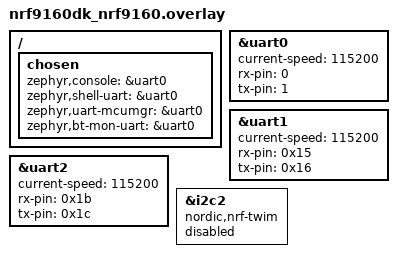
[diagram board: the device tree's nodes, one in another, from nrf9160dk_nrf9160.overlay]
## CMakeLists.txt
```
# SPDX-License-Identifier: Apache-2.0

cmake_minimum_required(VERSION 3.13.1)

set(DTC_OVERLAY_FILE "${CMAKE_CURRENT_SOURCE_DIR}/${BOARD}.overlay")

find_package(Zephyr REQUIRED HINTS $ENV{ZEPHYR_BASE})
project(hello_world)

target_include_directories(app PRIVATE
src)

target_sources(app PRIVATE
src/main.cpp
src/memtracer.cpp
src/eventpack.cpp
src/eventmanager.cpp
src/watchdog.cpp
src/heartbeat.cpp
src/test_uart00.cpp
src/test_uart01.cpp
src/test_uart02.cpp)
```

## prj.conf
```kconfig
########################################
#################Atrack#################
########################################
#recommand use non-secure mode because lte lib must in non-secure
# -Og debug can change to -O0, refer to compiler_flags.cmake
CONFIG_DEBUG=y

# enable cpp
CONFIG_CPLUSPLUS=y
CONFIG_STD_CPP11=y
CONFIG_LIB_CPLUSPLUS=y

# enable libs
CONFIG_NEWLIB_LIBC=y
CONFIG_NEWLIB_LIBC_FLOAT_PRINTF=y
CONFIG_FPU=y

# 3 uarts move to external pin, plz use usb-jlink JLinkRTTViewerExe watch log
CONFIG_UART_CONSOLE=n
CONFIG_USE_SEGGER_RTT=y
CONFIG_RTT_CONSOLE=y
#for input message
CONFIG_SEGGER_RTT_BUFFER_SIZE_DOWN=2048
CONFIG_SEGGER_RTT_BUFFER_SIZE_UP=2048

# reboot utility
CONFIG_REBOOT=y

# Fatal error reboot
CONFIG_WATCHDOG=y

# Json utility, if u need
###CONFIG_JSON_LIBRARY=y

# enable mcuboot prevent .text overflow, need pip3 install cryptography
CONFIG_BOOTLOADER_MCUBOOT=y
```

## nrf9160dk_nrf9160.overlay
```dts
/*
 * Copyright (c) 2021 Nordic Semiconductor ASA
 *
 * SPDX-License-Identifier: Apache-2.0
 */

/ {
	chosen {
		zephyr,console     = &uart0;
		zephyr,shell-uart  = &uart0;
		zephyr,uart-mcumgr = &uart0;
		zephyr,bt-mon-uart = &uart0;
	};
};

&uart0 {
        current-speed = <115200>;
        status = "okay";
        rx-pin = <0>;
        tx-pin = <1>;
        /delete-property/ cts-pin;
        /delete-property/ rts-pin;
};

&uart1 {
        current-speed = <115200>;
        status = "okay";
        rx-pin = <0x15>;
        tx-pin = <0x16>;
        /delete-property/ cts-pin;
        /delete-property/ rts-pin;
};

&uart2 {
        current-speed = <115200>;
        status = "okay";
        rx-pin = <0x1b>;
        tx-pin = <0x1c>;
        /delete-property/ cts-pin;
        /delete-property/ rts-pin;
};

/*prevent irq conflict with uart2*/
&i2c2 {
        compatible = "nordic,nrf-twim";
		status = "disabled";
};
```

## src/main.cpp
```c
/*
 * Copyright (c) 2012-2014 Wind River Systems, Inc.
 *
 * SPDX-License-Identifier: Apache-2.0
 */

#if defined(__ZEPHYR__)
#include <zephyr.h>
#include <device.h>
#include <devicetree.h>
#include <drivers/uart.h>
#include <drivers/i2c.h>
#include <drivers/sensor.h>
#include <drivers/flash.h>
#include <storage/flash_map.h>
//#include <data/json.h>
#endif

#include <stdint.h>
#include <unistd.h>
#include <stdio.h>
#include <stddef.h>
#include <string.h> //for memset
#include <math.h>

#include <string>
#include <list>
#include <vector>
#include <map>

#if !defined(__ZEPHYR__) //for x86
#include "memtracer.h"
#endif

#include "global.h"
#include "eventfunctor.h"
#include "eventpack.h"
#include "eventmanager.h"
#include "watchdog.h"
#include "heartbeat.h"
#include "test_uart00.h"
#include "test_uart01.h"
#include "test_uart02.h"

#define THREAD_STACKSIZE  4096

#if defined(__ZEPHYR__)
K_THREAD_STACK_DEFINE(stack_application_area, THREAD_STACKSIZE);
static struct k_work_q    s_application_work_q;
#endif

//~/ncs/zephyr/include/data/json.h
/*static void test_json_obj_arr_encoding()
{
  typedef struct _test_struct_t
  {
    //char  some_string[64]; //will crash in json lib
    char* some_string;
    int   some_int;
    bool  some_bool;
  }test_struct_t;

  test_struct_t ts = 
  {
    //.some_string  = {0},
    .some_string  = "zephyr 123",
    .some_int     = 42,
    .some_bool    = true,
  };

  struct json_obj_descr test_descr[] = 
  {
    JSON_OBJ_DESCR_PRIM(test_struct_t, some_string,  JSON_TOK_STRING),
    JSON_OBJ_DESCR_PRIM(test_struct_t, some_int,     JSON_TOK_NUMBER),
    JSON_OBJ_DESCR_PRIM(test_struct_t, some_bool,    JSON_TOK_TRUE),
  };

  char buffer[256] = {0};
  
  json_obj_encode_buf(test_descr, ARRAY_SIZE(test_descr), &ts, buffer, sizeof(buffer));
  
  printk("%s\n", buffer);
}

static void test_json_obj_arr_decoding()
{
  struct  test_struct 
  {
    char*   some_string;
    int     some_int;
    bool    some_bool;
  };

  struct test_struct ts = 
  {
    .some_string  = "zephyr 000",
    .some_int     = 0,
    .some_bool    = false,
  };

  struct json_obj_descr test_descr[] = 
  {
    JSON_OBJ_DESCR_PRIM(struct test_struct, some_string,  JSON_TOK_STRING),
    JSON_OBJ_DESCR_PRIM(struct test_struct, some_int,     JSON_TOK_NUMBER),
    JSON_OBJ_DESCR_PRIM(struct test_struct, some_bool,    JSON_TOK_TRUE),
  };

  char encoded[] =  "{\"some_string\":\"zephyr 123\","
                    "\"some_int\":42,\"some_bool\":true,"
                    "}";

  json_obj_parse(encoded, sizeof(encoded) - 1, test_descr, ARRAY_SIZE(test_descr), &ts);

  printk("%s : %d : %d\n", ts.some_string, ts.some_int, ts.some_bool);
}*/


//"memory" = memory barrier, save to register not memory, in -Og -O1 -O2 -O3 of gcc
int test_asm00()
{
  int ret;
  uint32_t arm_reg_input[4] = {0x01};

  arm_reg_input[0] += 1;
  __asm__ volatile("" ::: "memory");
  arm_reg_input[1] += 1;
 
  ret = arm_reg_input[0]+arm_reg_input[1];
  
  return ret;
}

int test_asm01()
{
  int ret;
  uint32_t arm_reg_input[4] = {0x01};
  
  __asm__ volatile("" ::: "memory");

  arm_reg_input[0] += 1;
  arm_reg_input[1] += 1;

  ret = arm_reg_input[0]+arm_reg_input[1];

  return ret;
}

//check https://docs.zephyrproject.org/latest/reference/kernel/threads/index.html?highlight=k_thread_create#c.k_thread_create
#if defined(__ZEPHYR__)
void main(void)
#else
int main(int argc, char* argv[])
#endif
{
  printf("main start\n");

#if defined(__ZEPHYR__)
  k_work_q_start( &s_application_work_q, 
                  stack_application_area,  
                  K_THREAD_STACK_SIZEOF(stack_application_area),
                  CONFIG_SYSTEM_WORKQUEUE_PRIORITY);
  
  watchdog_init_and_start(&s_application_work_q);//Hank request work

  uint32_t output           = 0x01;
  uint32_t arm_reg_input[4] = {0};
  arm_reg_input[0]          = 0x02;
  arm_reg_input[1]          = 0x03;
  arm_reg_input[2]          = 0x04;
  arm_reg_input[3]          = 0x05;
  
  __asm__ volatile 
  ( 
    "add r0, r1 \n\t"
    "add r0, r2 \n\t"
    "add r0, r3 \n\t"
    "mov %0, r0 \n\t"
    : "=r"(output)
    : "r"(arm_reg_input[0]), "r"(arm_reg_input[1]), "r"(arm_reg_input[2]), "r"(arm_reg_input[3])
  );
#endif

  test_asm00();
  test_asm01();

  HeartBeat_Init();
  Test_Uart00_Init();
  Test_Uart01_Init();
  Test_Uart02_Init();

  for(int i=0; i<30; i++)
  {
    printf("main loop: %d\n", i);
    HeartBeat_BroadCast();

#if defined(__ZEPHYR__)
    k_usleep(SLEEP_HEARTBEAT);
#else
    usleep(SLEEP_HEARTBEAT);
#endif

    HeartBeat_LiveCheck();

#if defined(__ZEPHYR__)
    k_usleep(SLEEP_HEARTBEAT);
#else
    usleep(SLEEP_HEARTBEAT);
#endif
  }

  Test_Uart00_Destory(); //for test seq
  Test_Uart01_Destory();
  Test_Uart02_Destory();
  HeartBeat_Destory();


  EventManager::Free();

  //////////////////enable this can see memory leak, in debug mode/////////////////////
  //int* a = new int[1];
  //int* a = (int*)malloc(sizeof(int));
#if !defined(__ZEPHYR__) //for x86
  dumpAlloc();
#endif

  printf("main end\n");
}
```

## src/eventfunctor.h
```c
#ifndef EVENT_FUNCTOR_H
#define EVENT_FUNCTOR_H

template<class ParamInfo> 
class EventFunctorBase
{
public:
	virtual ~EventFunctorBase()	{ }
	virtual void*	GetMember()				= 0;
	virtual void	Call(ParamInfo* event)	= 0;
};

template<class ParamInfo> 
class EventFunctor : public EventFunctorBase<ParamInfo>
{
public:
	typedef void (*MemberPtr)(ParamInfo*); //ParamInfo is func's paramater

	EventFunctor(MemberPtr callmember)
	{
		m_pCallMember = callmember;
	}

	virtual ~EventFunctor()	{ }

	virtual void* GetMember() 
	{ 
		return (void*)m_pCallMember;
	}

	virtual void Call(ParamInfo* event)
	{ 
		(*m_pCallMember)(event);
	}

private:
	MemberPtr	m_pCallMember;
};

#endif // I_FUNCTOR_H
```

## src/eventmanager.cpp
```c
#if defined(__ZEPHYR__)
#include <zephyr.h>
#else
#include <pthread.h>
#endif

#include <stddef.h>
#include <vector>
#include <map>

#if !defined(__ZEPHYR__) //for x86
#include "memtracer.h"
#endif

#include "eventfunctor.h"
#include "eventpack.h"
#include "eventmanager.h"

#if defined(__ZEPHYR__)
K_MUTEX_DEFINE(s_evtmanager_mutex);
#else
pthread_mutex_t s_evtmanager_mutex;
#endif

enum {
EVENTMGR_CONNECT,
EVENTMGR_DISCONNECT,
EVENTMGR_SEND
};

static EventManager* evtmanager_instance = NULL;

EventManager* EventManager::Get()
{
    if (!evtmanager_instance)
      evtmanager_instance = new EventManager();

    return evtmanager_instance;
}

void EventManager::Free()
{
    if( evtmanager_instance )
    {
      delete evtmanager_instance;
      evtmanager_instance = NULL;
    }
}

EventManager::EventManager()
{
#if !defined(__ZEPHYR__)
  pthread_mutex_init(&s_evtmanager_mutex, NULL);
#endif
}

EventManager::~EventManager()
{
#if !defined(__ZEPHYR__)
  pthread_mutex_destroy(&s_evtmanager_mutex);
#endif
}

void EventManager::ProcessEvent(int type, int messageID, void* callmember, EventPack* event)
{
#if defined(__ZEPHYR__)
    k_mutex_lock(&s_evtmanager_mutex, K_FOREVER);
#else
    pthread_mutex_lock(&s_evtmanager_mutex);
#endif

    unsigned int                      i;
    unsigned int                      size;
    unsigned int                      shift_p;
    unsigned int                      remain_size_vit;
    unsigned int                      remain_size_mit;
    EventMessageSlot_Vector::iterator vit;
    EventMessageSlot_Map::iterator    mit;
    EventMessageSlot_Map::iterator    tmp;
    EventFunctor<EventPack>*          functor;

    switch(type)
    {
        case EVENTMGR_CONNECT:
                functor = new EventFunctor<EventPack>((EventFunctor<EventPack>::MemberPtr)callmember);
                m_EventMessageSlotMap[messageID].push_back(functor);
                break;

        case EVENTMGR_DISCONNECT:
                mit             = m_EventMessageSlotMap.begin();
                remain_size_mit = m_EventMessageSlotMap.size();
                while(remain_size_mit > 0)
                {
                    shift_p         = 0;
                    remain_size_vit = mit->second.size();

                    while(remain_size_vit > 0)
                    {
                        if( mit->second[shift_p]->GetMember() == callmember )
                        {
                          vit = mit->second.begin() + shift_p;
                          delete *vit; //delete vector
                          mit->second.erase(vit);
                        }
                        else
                        {
                          shift_p++;
                        }

                        remain_size_vit--;
                    }

                    //empty slot remove
                    if( mit->second.size() <= 0 )
                    {
                        tmp = mit; //content copy
                        //mit++;
                        //m_EventMessageSlotMap.erase(tmp);
                        mit = m_EventMessageSlotMap.erase(tmp);
                    }
                    else
                    {
                        mit++;
                    }

                    remain_size_mit--;
                }
                break;

        case EVENTMGR_SEND:
#if !defined(__ZEPHYR__) || defined(CONFIG_DEBUG)
                printf("Start Source=%d~~~\n", event->GetSourceId());
#endif
                mit = m_EventMessageSlotMap.find(event->GetMessageId());
                if( mit != m_EventMessageSlotMap.end() ) //prevent null map
                {
                    size  = mit->second.size();

                    for ( i=0; i<size; i++)
                            mit->second[i]->Call(event);
                }
#if !defined(__ZEPHYR__) || defined(CONFIG_DEBUG)
                printf("End   Source=%d###\n", event->GetSourceId());
#endif
                break;
    }


#if defined(__ZEPHYR__)
    k_mutex_unlock(&s_evtmanager_mutex);
#else
    pthread_mutex_unlock(&s_evtmanager_mutex);
#endif
}

void EventManager::ConnectEventSlot(int messageID, void* callmember)
{
    this->ProcessEvent(EVENTMGR_CONNECT, messageID, callmember, NULL);
}

void EventManager::DisconnectEventSlot(void* callmember)
{
    this->ProcessEvent(EVENTMGR_DISCONNECT, 0, callmember, NULL);
}

void EventManager::SendEventMessage(EventPack* event)
{
    this->ProcessEvent(EVENTMGR_SEND, 0, NULL, event);
}
```

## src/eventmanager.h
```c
#ifndef EVENT_MANAGER_H
#define EVENT_MANAGER_H

class EventManager
{
public:
	
	typedef std::vector<EventFunctorBase<EventPack>*>	EventMessageSlot_Vector;
	typedef std::map<int, EventMessageSlot_Vector>		EventMessageSlot_Map; //<message_ID, EventPack_Vector>

    static EventManager* Get();
    static void Free();
	EventManager();
	~EventManager();

	// event sinks
	//void	ConnectEventSlot(int messageID, EventFunctorBase<EventPack>* functor);
	void 	ProcessEvent(int type, int messageID, void* callmember, EventPack* event);
	void	ConnectEventSlot(int messageID, void* callmember);
	void	DisconnectEventSlot(void* callmember);
	void	SendEventMessage(EventPack* event);
	
private:
	// event sinks
	EventMessageSlot_Map	m_EventMessageSlotMap;
};

#endif /// EVENT_MANAGER_H
```

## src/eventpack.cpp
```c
#include <stdio.h>

#if !defined(__ZEPHYR__) //for x86
#include "memtracer.h"
#endif

#include "eventfunctor.h"
#include "eventpack.h"

int EVT_HEARTBEAT_BROADCAST = 0x0000;
int EVT_HEARTBEAT_FEEDBACK  = 0x0001;
int SRC_HEARTBEAT           = 0x0002;
int SRC_TEST_UART00         = 0x0003;
int SRC_TEST_UART01         = 0x0004;
int SRC_TEST_UART02         = 0x0005;

EventPack::EventPack( int messageid )
{
  this->SetMessageId(messageid);
}

EventPack::~EventPack()
{
}

void EventPack::SetMessageId( int id ) 
{ 
  m_messageid = id; 
}

int EventPack::GetMessageId() 
{ 
  return m_messageid; 
}

void EventPack::SetSourceId( int id ) 
{ 
  m_sourceid = id;
}
	
int EventPack::GetSourceId() 
{ 
  return m_sourceid; 
}

void EventPack::SetText( char* text ) 
{ 
  sprintf(m_text, "%s", text);
}
	
char* EventPack::GetText() 
{ 
  return m_text; 
}
```

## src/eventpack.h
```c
#ifndef SDK_EVENT_H
#define SDK_EVENT_H

extern int EVT_HEARTBEAT_BROADCAST;
extern int EVT_HEARTBEAT_FEEDBACK;
extern int SRC_HEARTBEAT;
extern int SRC_TEST_UART00;
extern int SRC_TEST_UART01;
extern int SRC_TEST_UART02;

class EventPack
{
public:
  EventPack( int messageid );
  ~EventPack();
      
  void  SetMessageId( int id );
  int	GetMessageId();

  void	SetSourceId( int id );
  int	GetSourceId();

  void	SetText( char* text );
  char*	GetText();

/******************************/      
  int		m_messageid;
  int		m_sourceid;
  char		m_text[256];
};

#endif	/// #define CONNECT_EVENT_H
```

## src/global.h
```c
#ifndef ATRACK_GLOBAL_H
#define ATRACK_GLOBAL_H

#define SLEEP_MINIMUM     100000  //for short time recv
#define SLEEP_LOOP        500000  //for thread sleep
#define SLEEP_HEARTBEAT   6000000 //6 sec

#endif
```

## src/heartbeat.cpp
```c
#if defined(__ZEPHYR__)
#include <zephyr.h>
#include <drivers/uart.h>
#include <power/reboot.h>
#endif

#include <stdint.h>
#include <string.h>
#include <stdio.h>
#include <vector>
#include <map>

#if !defined(__ZEPHYR__) //for x86
#include "memtracer.h"
#endif

#include "global.h"

#include "eventfunctor.h"
#include "eventpack.h"
#include "eventmanager.h"
#include "heartbeat.h"

std::map<int, bool> s_heartbeat_live_map;

void HeartBeat_BroadCast()
{
  printf("BroadCast\n");
  
  EventPack* event = new EventPack(EVT_HEARTBEAT_BROADCAST);

  event->SetSourceId(SRC_HEARTBEAT);
  EventManager::Get()->SendEventMessage(event);

  delete event;
}

static void HeartBeat_FeedBack(EventPack* event)
{
  int srcid = event->GetSourceId();
  s_heartbeat_live_map[srcid] = true;
}

int HeartBeat_LiveCheck()
{
  uint32_t  total_live;
  char      buf[64];
  
  total_live = 0;
  for (auto& mit : s_heartbeat_live_map)
  {
    sprintf(buf,"id=%d, live=%d\n", mit.first, mit.second);
    printf("%s", buf);
    
    if( mit.second )
      total_live++;

    mit.second = false;
  }

  if( total_live < s_heartbeat_live_map.size() )
  {
#if defined(__ZEPHYR__)
    sys_reboot(0);
#else
    exit(0);
#endif
  }
  
    
  return total_live;
}

void HeartBeat_Init()
{
  s_heartbeat_live_map.insert({SRC_TEST_UART00, false });
  s_heartbeat_live_map.insert({SRC_TEST_UART01, false });
  s_heartbeat_live_map.insert({SRC_TEST_UART02, false });

  //EventManager::Get()->ConnectEventSlot(EVT_HEARTBEAT_FEEDBACK, new EventFunctor<EventPack>(&HeartBeat_FeedBack));
  EventManager::Get()->ConnectEventSlot(EVT_HEARTBEAT_FEEDBACK, (void*)&HeartBeat_FeedBack);
}

void HeartBeat_Destory()
{
  EventManager::Get()->DisconnectEventSlot((void*)&HeartBeat_FeedBack);

  s_heartbeat_live_map.clear();
}
```

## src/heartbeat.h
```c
#ifndef HEARTBEAT_H
#define HEARTBEAT_H

extern void HeartBeat_BroadCast();
extern int  HeartBeat_LiveCheck();
extern void HeartBeat_Init();
extern void HeartBeat_Destory();

#endif
```

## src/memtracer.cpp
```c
#if !defined(__ZEPHYR__) //for x86

#include <assert.h>
#include <stdio.h>
#include <stdlib.h>
#include <string.h>

#define MEM_TRACER_C 1
#include "memtracer.h"

#ifdef __cplusplus
extern "C" {
#endif
// Allocation descriptors HashMap related functions
static size_t genHash(size_t max, void* ptr)
{
	size_t key= (size_t)ptr;
	return (key % max);
}

static int nextNotPow2(int num)
{
	int nextnotpow2=num;
	while ( (nextnotpow2!=0) && ((nextnotpow2 & (nextnotpow2-1)) == 0) ) 
	{
		nextnotpow2++;
	}
	return nextnotpow2;
}

/**
   Returns an empty hash of the chosen size
 */
allochashmap* hashmap_Init(int size)
{
	int asize=nextNotPow2(size);
	allochashmap* map=(allochashmap*) malloc(sizeof(allochashmap));
	assert((NULL!=map) &&  MSG_ERR_HM_MALLOC);
	map->size=asize;
	map->table=(allocnode**)calloc(asize,sizeof(allocnode));
	if (NULL==map->table) 
	{
		free(map);
		map=NULL;
	}
	assert((NULL!=map) &&  MSG_ERR_HM_MALLOC);
	return(map);
}

/**
   Free the hash with ALL its content, leaked pointers will be freed.
 */
void hashmap_Destroy(allochashmap* map)
{
	size_t i=0;
	for(i=0; i<map->size; ++i) 
	{
		while(map->table[i] != NULL)
		{
			allocnode* next=map->table[i]->next;
			free(map->table[i]->info->file);
			//free(map->table[i]->info->ptr); //external pointer as _CrtDumpMemoryLeaks();
			free(map->table[i]->info);
			free(map->table[i]);
			map->table[i]=next;
		}
	}
	free(map->table);
	map->table=NULL;
	free(map);
	map=NULL;
}

/**
   Remove the allocation descriptor of the given pointer, returns true: found, false:no found
 */
bool hashmap_Delete(allochashmap* map, void* ptr)
{
	size_t		idx	= genHash(map->size, ptr);
	allocnode*	cur	= map->table[idx];
	allocnode*	prev= map->table[idx];

	while(cur != NULL)
	{
		if (cur->info->ptr == ptr) 
		{
			//allocnode* found=cur;
			if (prev==cur) 
			{
				map->table[idx]=cur->next;
			}
			else
			{
				prev->next=cur->next;
			}
			
			free(cur->info->file);	//free(found->info->file);
			free(cur->info);		//free(found->info);
			free(cur);				//free(found);
			
			return true;
		}
		else
		{
			prev=cur;
			cur=cur->next;
		}
	}
	
	return false;
}

/**
   Print out the content of the hashmap using the given function as allocated block address - block size and stats on the load
 */
void hashmap_Print(allochashmap* map, int outp(const char *format, ...))
{
	//int	load	= 0;
	int		isfirst	= 1;
	
	for(size_t i=0; i<map->size; ++i)
	{
		allocnode* nextn = map->table[i];
		
		//if (nextn != NULL)
		//	load++;
		while(nextn != NULL)
		{
			if (isfirst)
			{
				isfirst = 0;
				outp("--- Memory Leak status ---\n");
			}
			
			outp("Addr:0x%016llX - Size: %llu allocated in %s:%d\n", (unsigned long long)nextn->info->ptr, (unsigned long long)nextn->info->size, nextn->info->file, nextn->info->line);
			nextn = nextn->next;
		}
	}
}

/**
   Insert a new allocation descriptor, returns hash key (pointer descriptor idx)
 */
size_t hashmap_Insert(allochashmap* map, allocdescr* data)
{
	size_t idx=genHash(map->size, data->ptr);
	allocnode* newnode= (allocnode*) calloc(1,sizeof(allocnode));
	assert((NULL!=newnode) &&  MSG_ERR_HM_MALLOC);
	newnode->info=data;
	newnode->next=map->table[idx];
	map->table[idx]=newnode;
	return idx;
}

/**
   Build an allocation descriptor
 */
allocdescr* buildAllocdescr(void* ptr, size_t size, const char* filename, int line)
{
	allocdescr* newn=(allocdescr*)malloc(sizeof(allocdescr));
	newn->ptr=ptr;
	newn->size=size;
	newn->file=(char*) malloc(50);
	strcpy(newn->file,filename);
	newn->line=line;
	return newn;
}

//--------------------------------------------------------------------------------------------
static allochashmap* allocMap=NULL;

void tracingInit()
{
	if (NULL == allocMap) 
	{
		allocMap=hashmap_Init(ALLOC_TABLE_SIZE);
	}
}

void* tracingMalloc(size_t size, const char* name, int line)
{
	tracingInit();
	void* ptr=malloc(size);
	hashmap_Insert(allocMap,buildAllocdescr(ptr,size,name,line));
	return ptr;
}

void* tracingRealloc(void* ptr, int size, const char* name, int line)
{
	tracingInit();
	hashmap_Delete(allocMap,ptr);
	void* ptrnew=realloc(ptr,size);
	hashmap_Insert(allocMap,buildAllocdescr(ptrnew,size,name,line));
	return ptr;
}

void* tracingCalloc(int num, int size, const char* name, int line)
{
	tracingInit();
	void* ptr=calloc(num,size);
	hashmap_Insert(allocMap,buildAllocdescr(ptr,num*size,name,line));
	return ptr;
}

void tracingFree(void* ptr)
{
	tracingInit();
	hashmap_Delete(allocMap,ptr);
	free(ptr);
}

void dumpAlloc()
{
    tracingInit();
	hashmap_Print(allocMap,&printf);
	hashmap_Destroy(allocMap);
}
#ifdef __cplusplus
}
#endif

#ifdef __cplusplus
void* operator new(size_t size) throw()
{
	return tracingMalloc(size,"-N/A-",0);
}

void* operator new(size_t size, const char* name, int line)
{
	return tracingMalloc(size,name,line);
}

//void* operator new[] (size_t size) throw(std::bad_alloc)
void* operator new[](size_t size) throw()
{
	return tracingMalloc(size,"-N/A-",0);
}

void * operator new[] (size_t size, const char* name, int line)
{
	return tracingMalloc(size,name,line);
}

void operator delete(void* ptr) throw()
{
	tracingFree(ptr);
}

void operator delete(void* ptr, const char* name, int line)
{
	tracingFree(ptr);
}

void operator delete[](void* ptr) throw()
{
	tracingFree(ptr);
}

void operator delete[](void* ptr, const char* name, int line)
{
	tracingFree(ptr);
}
#endif //end __cplusplus

#endif //end !defined(__ZEPHYR__)
```

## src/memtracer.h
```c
#ifndef MEM_TRACER_H
#define MEM_TRACER_H

#include <stddef.h>

#ifdef __cplusplus
#include <new>
extern "C" {
#endif

#define MSG_ERR_HM_MALLOC "malloc() failed for allocation descriptors hashmap."

// Allocation descriptors hashmap size, increase to lower the load shown by dumpAlloc
//#define ALLOC_TABLE_SIZE 1733
#define ALLOC_TABLE_SIZE 4096

// Allocation descriptor hashmap structs
typedef struct allocdescr
{
	void*	ptr;
	char*	file;
	int		line;
	size_t	size;
} allocdescr;

typedef struct allocnode
{
	allocdescr*			info;
	struct allocnode*	next;
} allocnode;

typedef struct allochashmap
{
	size_t		size;
	allocnode** table;
} allochashmap;

void*	tracingMalloc(size_t size, const char* name, int line);
void*	tracingRealloc(void* ptr, int size, const char* name, int line);
void*	tracingCalloc(int num, int size, const char* name, int line);
void	tracingFree(void* ptr);
void	dumpAlloc();

#ifndef MEM_TRACER_C
	#define malloc(s) tracingMalloc(s,__FILE__,__LINE__)
	#define realloc(p,s) tracingRealloc(p,s,__FILE__,__LINE__)
	#define calloc(n,s) tracingCalloc(n,s,__FILE__,__LINE__)
	#define free(p) tracingFree(p)
#endif //ifndef MEM_TRACER_C

#ifdef __cplusplus
}
#endif


#ifndef MEM_TRACER_C
#ifdef __cplusplus
	//void*	operator new(size_t) throw(std::bad_alloc);
	void*	operator new(size_t) throw();
	void*	operator new(size_t, const char* name, int line);
	//void*	operator new[] (size_t) throw(std::bad_alloc);
	void*	operator new[](size_t) throw();
	void*	operator new[] (size_t, const char* name, int line);
	
	void	operator delete(void*) throw();
	void	operator delete(void*, const char* name, int line);
	void	operator delete[](void*) throw();
	void	operator delete[](void*, const char* name, int line);
			
	#define tracingNew new (__FILE__,__LINE__)
	#define tracingDelete delete
	#define new tracingNew
	#define delete tracingDelete
#endif //ifdef _cplusplus
#endif //ifndef MEM_TRACER_C


#endif //ifndef MEM_TRACER_H 
```

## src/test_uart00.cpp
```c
#if defined(__ZEPHYR__)
#include <zephyr.h>
#include <drivers/uart.h>
#else
#include <pthread.h>
#endif
#include <unistd.h>
#include <string.h>
#include <stdio.h>
#include <vector>
#include <map>

#if !defined(__ZEPHYR__) //for x86
#include "memtracer.h"
#endif

#include "global.h"
#include "eventfunctor.h"
#include "eventpack.h"
#include "eventmanager.h"
#include "heartbeat.h"
#include "test_uart00.h"

#define THREAD_STACKSIZE  4096
#define UART_BUFSIZE      2048

enum
{
  UART_READ,
  UART_WRITE
};

enum
{
  FEEDBACK_READ,
  FEEDBACK_WRITE
};

#if defined(__ZEPHYR__)
K_THREAD_STACK_DEFINE(s_test_uart00_stack, THREAD_STACKSIZE);
K_MUTEX_DEFINE(s_test_uart00_fifo_mutex);
static struct k_thread	s_kthread_test_uart00   = {0};
#else
pthread_mutex_t 		s_test_uart00_fifo_mutex;
static pthread_t        s_kthread_test_uart00	= 0;
#endif


static volatile int     s_test_uart00_work      = 0;
static volatile int     s_test_uart00_loop      = 0;

static volatile bool    s_test_uart00_heartbeat = false;
static volatile int     s_test_uart00_shift     = 0;
static char*            s_test_uart00_buf       = NULL;

static void Test_Uart00_OnHeartBeat(EventPack* event)
{
  s_test_uart00_heartbeat = true;
}

static void Test_Uart00_HeartBeat_Reponse()
{
  EventPack* event = new EventPack(EVT_HEARTBEAT_FEEDBACK);

  event->SetSourceId(SRC_TEST_UART00);
  EventManager::Get()->SendEventMessage(event);

  delete event;
}

static bool Test_Uart00_Fifo_Process(int type, char* read_str, char write_char)
{
  int ret = false;

#if defined(__ZEPHYR__)
  k_mutex_lock(&s_test_uart00_fifo_mutex, K_FOREVER);
#else
  pthread_mutex_lock(&s_test_uart00_fifo_mutex);
#endif
  
  switch(type)
  {
    case UART_READ:
              if( s_test_uart00_shift > 0 )
              {
                if( s_test_uart00_buf[s_test_uart00_shift-1] == '\n'
                    ||
                    s_test_uart00_buf[s_test_uart00_shift-1] == '\r')
                {
                  strcpy(read_str, s_test_uart00_buf);
                  
                  s_test_uart00_shift = 0;
                  memset(s_test_uart00_buf, 0, UART_BUFSIZE);
                
                  ret = true;
                }
              }
              break;
    
    case UART_WRITE:
              //buf 0~2047, data 0~2046, 2047 string end always 0x00
              if( s_test_uart00_shift < UART_BUFSIZE-1 )
              {
                s_test_uart00_buf[s_test_uart00_shift] = write_char;
                s_test_uart00_shift++;
              }
              break;
  }

#if defined(__ZEPHYR__)
  k_mutex_unlock(&s_test_uart00_fifo_mutex);
#else
  pthread_mutex_unlock(&s_test_uart00_fifo_mutex);
#endif

  return ret;
}

#if defined(__ZEPHYR__)
static void uart_cb0(const struct device* dev, void* user_data)
{
  char c;
  
  uart_irq_update(dev);
  if (uart_irq_rx_ready(dev)) 
  {
    while (uart_fifo_read(dev, (uint8_t*)&c, 1)) 
    {
      Test_Uart00_Fifo_Process(UART_WRITE, NULL, c);
    }
  }
}

static void Test_Uart00_Poll_Out(const struct device* uart_dev, char* data, uint32_t len)
{
    char      c;
    uint32_t  i;

    for (i = 0; i<len; i++) 
    {
      uart_poll_out(uart_dev, data[i]);

      if( data[i] == 0x0a )
      {
        c = 0x0d; //return
        uart_poll_out(uart_dev, c);
      }
    }
}
#endif

#if defined(__ZEPHYR__)
static void Test_Uart00_Thread(void* p0, void* p1, void* p2)
#else
static void* Test_Uart00_Thread(void* pparam)
#endif
{
  s_test_uart00_loop = 1;

  char* local_buf             = (char*)calloc(UART_BUFSIZE, sizeof(char));
#if defined(__ZEPHYR__)
  const struct device* uart0  = device_get_binding("UART_0");

  uart_irq_callback_set(uart0, uart_cb0);
  uart_irq_rx_enable(uart0);
#endif

  while(s_test_uart00_work)
  {
    if( Test_Uart00_Fifo_Process(UART_READ, local_buf, 0) )
    {
      //do something here
      // ...
      
      memset(local_buf, 0, UART_BUFSIZE);
    }

#if defined(__ZEPHYR__)
    //Test_Uart00_Poll_Out(uart0, "test uart00", strlen("test uart00"));
#endif

    if( s_test_uart00_heartbeat )
    {
      s_test_uart00_heartbeat = 0;
      Test_Uart00_HeartBeat_Reponse();
    }

#if defined(__ZEPHYR__)
    k_usleep(SLEEP_LOOP);
#else
    usleep(SLEEP_LOOP);
#endif
  }

#if defined(__ZEPHYR__)
  uart_irq_rx_disable(uart0);
  uart_irq_callback_set(uart0, NULL);
#endif

  free(local_buf);

  s_test_uart00_loop = 0;

#if !defined(__ZEPHYR__)
  return NULL;
#endif
}

void Test_Uart00_Init()
{
  //EventManager::Get()->ConnectEventSlot(EVT_HEARTBEAT_BROADCAST, new EventFunctor<EventPack>(&Test_Uart00_OnHeartBeat));
  EventManager::Get()->ConnectEventSlot(EVT_HEARTBEAT_BROADCAST, (void*)&Test_Uart00_OnHeartBeat);

  s_test_uart00_buf = (char*)calloc(UART_BUFSIZE, sizeof(char));
  
  s_test_uart00_work  = 1;
#if defined(__ZEPHYR__)
  k_thread_create(&s_kthread_test_uart00, //local kthread_softuart will crash in k_sleep
                  s_test_uart00_stack, 
                  THREAD_STACKSIZE,
                  Test_Uart00_Thread, 
                  NULL, 
                  NULL, 
                  NULL,
                  0, 
                  K_INHERIT_PERMS, 
                  K_NO_WAIT);
#else
  pthread_attr_t	pattr;
  pthread_attr_init(&pattr);
  pthread_attr_setdetachstate(&pattr, PTHREAD_CREATE_DETACHED);
  pthread_create(&s_kthread_test_uart00, &pattr, Test_Uart00_Thread, NULL);
  pthread_attr_destroy(&pattr);
#endif
}

void Test_Uart00_Destory()
{
  s_test_uart00_work = 0; //need before k_sem_reset
  while( s_test_uart00_loop )
  {
#if defined(__ZEPHYR__)
    k_usleep(SLEEP_LOOP); //6 second
#else
    usleep(SLEEP_LOOP);
#endif
  }

  free(s_test_uart00_buf);

  EventManager::Get()->DisconnectEventSlot((void*)&Test_Uart00_OnHeartBeat);
}
```

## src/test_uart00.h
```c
#ifndef TEST_UART00_H
#define TEST_UART00_H

extern void Test_Uart00_Init();
extern void Test_Uart00_Destory();

#endif
```
